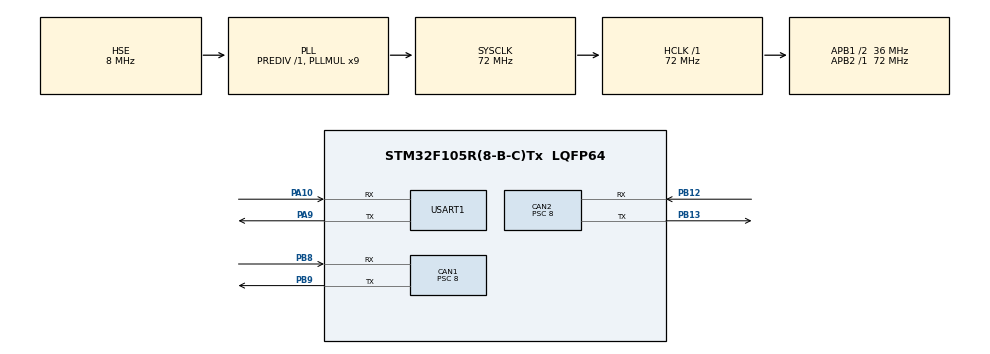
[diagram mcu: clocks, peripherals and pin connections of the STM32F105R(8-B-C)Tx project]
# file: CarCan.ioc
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CAN1.ABOM=DISABLE
CAN1.AWUM=DISABLE
CAN1.BS1=CAN_BS1_4TQ
CAN1.BS2=CAN_BS2_4TQ
CAN1.CalculateBaudRate=500000
CAN1.CalculateTimeBit=1999.99
CAN1.CalculateTimeQuantum=222.22222222222223
CAN1.Prescaler=8
CAN1.SJW=CAN_SJW_1TQ
CAN2.ABOM=ENABLE
CAN2.AWUM=ENABLE
CAN2.BS1=CAN_BS1_4TQ
CAN2.BS2=CAN_BS2_4TQ
CAN2.CalculateBaudRate=500000
CAN2.CalculateTimeBit=1999.99
CAN2.CalculateTimeQuantum=222.22222222222223
CAN2.Prescaler=8
CAN2.SJW=CAN_SJW_1TQ
Mcu.Family=STM32F1
Mcu.Name=STM32F105R(8-B-C)Tx
Mcu.Package=LQFP64
NVIC.CAN1_RX0_IRQn=true\:1\:0\:true\:false\:true\:true\:true
NVIC.CAN2_RX1_IRQn=true\:1\:0\:true\:false\:true\:true\:true
NVIC.PriorityGroup=NVIC_PRIORITYGROUP_2
NVIC.TIM7_IRQn=true\:0\:0\:false\:false\:true\:true\:true
PA10.Mode=Asynchronous
PA10.Signal=USART1_RX
PA13.Mode=Serial_Wire
PA13.Signal=SYS_JTMS-SWDIO
PA14.Mode=Serial_Wire
PA14.Signal=SYS_JTCK-SWCLK
PA9.Mode=Asynchronous
PA9.Signal=USART1_TX
PB12.Mode=CAN_Activate
PB12.Signal=CAN2_RX
PB13.Mode=CAN_Activate
PB13.Signal=CAN2_TX
PB8.Mode=CAN_Activate
PB8.Signal=CAN1_RX
PB9.Mode=CAN_Activate
PB9.Signal=CAN1_TX
PD0-OSC_IN.Mode=HSE-External-Oscillator
PD0-OSC_IN.Signal=RCC_OSC_IN
PD1-OSC_OUT.Mode=HSE-External-Oscillator
PD1-OSC_OUT.Signal=RCC_OSC_OUT
ProjectManager.HeapSize=0x200
ProjectManager.StackSize=0x400
ProjectManager.TargetToolchain=MDK-ARM V5.27
RCC.AHBFreq_Value=72000000
RCC.APB1CLKDivider=RCC_HCLK_DIV2
RCC.APB1Freq_Value=36000000
RCC.APB1TimFreq_Value=72000000
RCC.APB2Freq_Value=72000000
RCC.APB2TimFreq_Value=72000000
RCC.HCLKFreq_Value=72000000
RCC.PLLMUL=RCC_PLL_MUL9
RCC.PLLSourceVirtual=RCC_PLLSOURCE_HSE
RCC.SYSCLKFreq_VALUE=72000000
RCC.SYSCLKSource=RCC_SYSCLKSOURCE_PLLCLK
RCC.USBFreq_Value=48000000
TIM7.AutoReloadPreload=TIM_AUTORELOAD_PRELOAD_ENABLE
TIM7.Period=1999
TIM7.Prescaler=71
USART1.VirtualMode=VM_ASYNC
VP_TIM7_VS_ClockSourceINT.Mode=Enable_Timer
board=custom

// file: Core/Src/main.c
/* USER CODE BEGIN Header */
/**
  ******************************************************************************
  * @file           : main.c
  * @brief          : Main program body
  ******************************************************************************
  * @attention
  *
  * <h2><center>&copy; Copyright (c) 2021 STMicroelectronics.
  * All rights reserved.</center></h2>
  *
  * This software component is licensed by ST under BSD 3-Clause license,
  * the "License"; You may not use this file except in compliance with the
  * License. You may obtain a copy of the License at:
  *                        opensource.org/licenses/BSD-3-Clause
  *
  ******************************************************************************
  */
/* USER CODE END Header */
#include "main.h"
#include "can.h"
#include "tim.h"
#include "usart.h"
#include "gpio.h"

/* USER CODE BEGIN Includes */
#include "stdio.h"

/* USER CODE END Includes */

void SystemClock_Config(void);

int main(void)
{

  /* MCU Configuration--------------------------------------------------------*/

  /* Reset of all peripherals, Initializes the Flash interface and the Systick. */
  HAL_Init();

  /* Configure the system clock */
  SystemClock_Config();

  /* Initialize all configured peripherals */
  MX_GPIO_Init();
  MX_CAN1_Init();
  MX_CAN2_Init();
  MX_USART1_UART_Init();
  MX_TIM7_Init();
  /* USER CODE BEGIN 2 */

  CAN1_FilterConfig();
  HAL_Delay(100);
  CAN2_FilterConfig();
  HAL_Delay(100);

//  HAL_CAN_Receive_IT(&hcan1, CAN_Filter_FIFO0);
//  HAL_CAN_Receive_IT(&hcan2, CAN_Filter_FIFO1);

  HAL_TIM_Base_Start_IT(&htim7);
  /* USER CODE END 2 */

  /* Infinite loop */
  /* USER CODE BEGIN WHILE */
  while (1)
  {

    HAL_Delay(1000);

    printf("test\r\n");
    /* USER CODE END WHILE */

  }
}

void SystemClock_Config(void)
{
  RCC_OscInitTypeDef RCC_OscInitStruct = {0};
  RCC_ClkInitTypeDef RCC_ClkInitStruct = {0};

  /** Initializes the RCC Oscillators according to the specified parameters
  * in the RCC_OscInitTypeDef structure.
  */
  RCC_OscInitStruct.OscillatorType = RCC_OSCILLATORTYPE_HSE;
  RCC_OscInitStruct.HSEState = RCC_HSE_ON;
  RCC_OscInitStruct.HSEPredivValue = RCC_HSE_PREDIV_DIV1;
  RCC_OscInitStruct.HSIState = RCC_HSI_ON;
  RCC_OscInitStruct.Prediv1Source = RCC_PREDIV1_SOURCE_HSE;
  RCC_OscInitStruct.PLL.PLLState = RCC_PLL_ON;
  RCC_OscInitStruct.PLL.PLLSource = RCC_PLLSOURCE_HSE;
  RCC_OscInitStruct.PLL.PLLMUL = RCC_PLL_MUL9;
  RCC_OscInitStruct.PLL2.PLL2State = RCC_PLL_NONE;
  if (HAL_RCC_OscConfig(&RCC_OscInitStruct) != HAL_OK)
  {
    Error_Handler();
  }
  /** Initializes the CPU, AHB and APB buses clocks
  */
  RCC_ClkInitStruct.ClockType = RCC_CLOCKTYPE_HCLK|RCC_CLOCKTYPE_SYSCLK
                              |RCC_CLOCKTYPE_PCLK1|RCC_CLOCKTYPE_PCLK2;
  RCC_ClkInitStruct.SYSCLKSource = RCC_SYSCLKSOURCE_PLLCLK;
  RCC_ClkInitStruct.AHBCLKDivider = RCC_SYSCLK_DIV1;
  RCC_ClkInitStruct.APB1CLKDivider = RCC_HCLK_DIV2;
  RCC_ClkInitStruct.APB2CLKDivider = RCC_HCLK_DIV1;

  if (HAL_RCC_ClockConfig(&RCC_ClkInitStruct, FLASH_LATENCY_2) != HAL_OK)
  {
    Error_Handler();
  }
  /** Configure the Systick interrupt time
  */
  __HAL_RCC_PLLI2S_ENABLE();
}

void Error_Handler(void)
{
  __disable_irq();
  while (1)
  {
  }
}

/************************ (C) COPYRIGHT STMicroelectronics *****END OF FILE****/
